AUTOSAR XML (schema 4-2-2)
package /AUTOSAR/Components
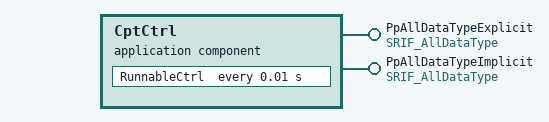
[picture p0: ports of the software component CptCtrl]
  application sw component type CptCtrl
    provide port PpAllDataTypeExplicit: provided-interface=SRIF_AllDataType
    provide port PpAllDataTypeImplicit: provided-interface=SRIF_AllDataType
    behavior IbCtrl
      timing event timingEvent_10: start-on-event=RunnableCtrl, period=0.01
      runnable RunnableCtrl: symbol=AppRunnableCtrl
        data-send-points:
          access DataSendPointsPrimitive: accessed-variable=PpAllDataTypeExplicit.dataElementPrimitive
          access dataSendPointsArray: accessed-variable=PpAllDataTypeExplicit.dataElementArray
          access dataSendPointsStruct: accessed-variable=PpAllDataTypeExplicit.dataElementStruct
        data-write-access:
          access dataWriteAccess_Primitive: accessed-variable=PpAllDataTypeImplicit.dataElementPrimitive
          access dataWriteAccess_Array: accessed-variable=PpAllDataTypeImplicit.dataElementArray
          access dataWriteAccess_Struct: accessed-variable=PpAllDataTypeImplicit.dataElementStruct
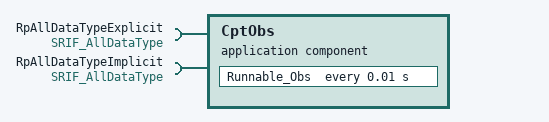
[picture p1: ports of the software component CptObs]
  application sw component type CptObs
    require port RpAllDataTypeExplicit: required-interface=SRIF_AllDataType
      required-com-specs:
        data-element=dataElementPrimitive, handle-never-received=true, init-value=0
        data-element=dataElementStruct, handle-never-received=true, init-value=fields=[0, 1, 2]
        data-element=dataElementArray, handle-never-received=true, init-value=[0]
    require port RpAllDataTypeImplicit: required-interface=SRIF_AllDataType
      required-com-specs:
        data-element=dataElementPrimitive, handle-never-received=true, init-value=0
        data-element=dataElementStruct, handle-never-received=true, init-value=fields=[0, 1, 2]
        data-element=dataElementArray, handle-never-received=true, init-value=[0]
    behavior IbObs
      timing event timingEvent_10: start-on-event=Runnable_Obs, period=0.01
      runnable Runnable_Obs: symbol=AppRunnable_Obs
        data-read-access:
          access dataReadAccess_Primitive: accessed-variable=RpAllDataTypeImplicit.dataElementPrimitive
          access dataReadAccess_Array: accessed-variable=RpAllDataTypeImplicit.dataElementArray
          access dataReadAccess_Struct: accessed-variable=RpAllDataTypeImplicit.dataElementStruct
        data-receive-point-by-arguments:
          access DataReceiveByArgPrimitive: accessed-variable=RpAllDataTypeExplicit.dataElementPrimitive
          access DataReceiveByArgArray: accessed-variable=RpAllDataTypeExplicit.dataElementArray
          access DataReceiveByArgStruct: accessed-variable=RpAllDataTypeExplicit.dataElementStruct
